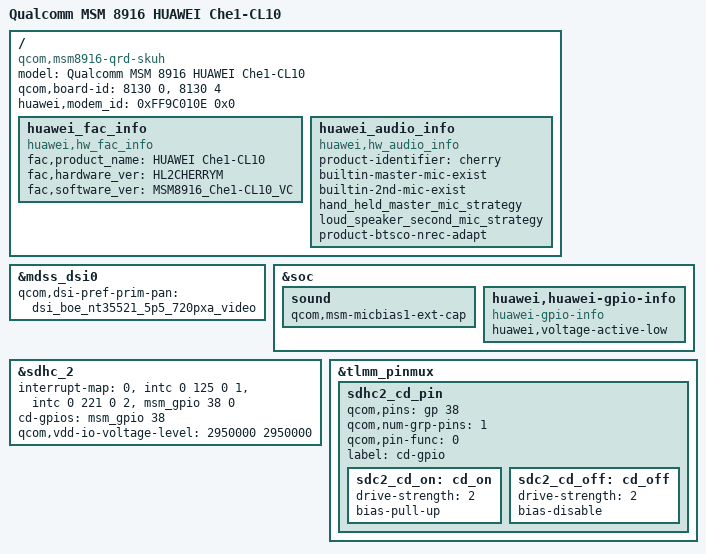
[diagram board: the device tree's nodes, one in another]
/* Copyright (c) 2014, The Linux Foundation. All rights reserved.
 *
 * This program is free software; you can redistribute it and/or modify
 * it under the terms of the GNU General Public License version 2 and
 * only version 2 as published by the Free Software Foundation.
 *
 * This program is distributed in the hope that it will be useful,
 * but WITHOUT ANY WARRANTY; without even the implied warranty of
 * MERCHANTABILITY or FITNESS FOR A PARTICULAR PURPOSE.  See the
 * GNU General Public License for more details.
 */

/dts-v1/;

#include "msm8916-qrd.dtsi"
#include "msm8916-memory.dtsi"
#include "cherry/msm8916-qrd_cherry.dtsi"
#include "cherry/huawei-nfc.dtsi"
 
/ {
	model = "Qualcomm MSM 8916 HUAWEI Che1-CL10";
	compatible = "qcom,msm8916-qrd-skuh", "qcom,msm8916-qrd", "qcom,msm8916", "qcom,qrd";
	qcom,board-id = <8130 0>, <8130 4>;
	huawei,modem_id = <0xFF9C010E 0x0>;
};

&mdss_dsi0 {
	qcom,dsi-pref-prim-pan = <&dsi_boe_nt35521_5p5_720pxa_video>;
	
};

&soc {

	sound {
        	qcom,msm-micbias1-ext-cap;
	};
	
	huawei,huawei-gpio-info {
		compatible = "huawei-gpio-info";
		huawei,voltage-active-low;
	};
};

/ {
	huawei_fac_info {
			  compatible = "huawei,hw_fac_info";
			  fac,product_name = "HUAWEI Che1-CL10";
			  fac,hardware_ver = "HL2CHERRYM";
			  fac,software_ver = "MSM8916_Che1-CL10_VC";
			  status = "ok";
	};
		
	huawei_audio_info {
        compatible = "huawei,hw_audio_info";
        product-identifier = "cherry";
        builtin-master-mic-exist;
        builtin-2nd-mic-exist;
        hand_held_master_mic_strategy;
        status = "ok";
        loud_speaker_second_mic_strategy;
        product-btsco-nrec-adapt;
    };
};

&sdhc_2 {
	interrupt-map = <0 &intc 0 125 0
		1 &intc 0 221 0
		2 &msm_gpio 38 0>;
	cd-gpios = <&msm_gpio 38 0x0>;
	qcom,vdd-io-voltage-level = <2950000 2950000>;
};

&tlmm_pinmux {
	sdhc2_cd_pin {
		qcom,pins = <&gp 38>;
		qcom,num-grp-pins = <1>;
		qcom,pin-func = <0>;
		label = "cd-gpio";
		sdc2_cd_on: cd_on {
			drive-strength = <2>;
			bias-pull-up;
		};
		sdc2_cd_off: cd_off {
			drive-strength = <2>;
			bias-disable;
		};
	};
};

